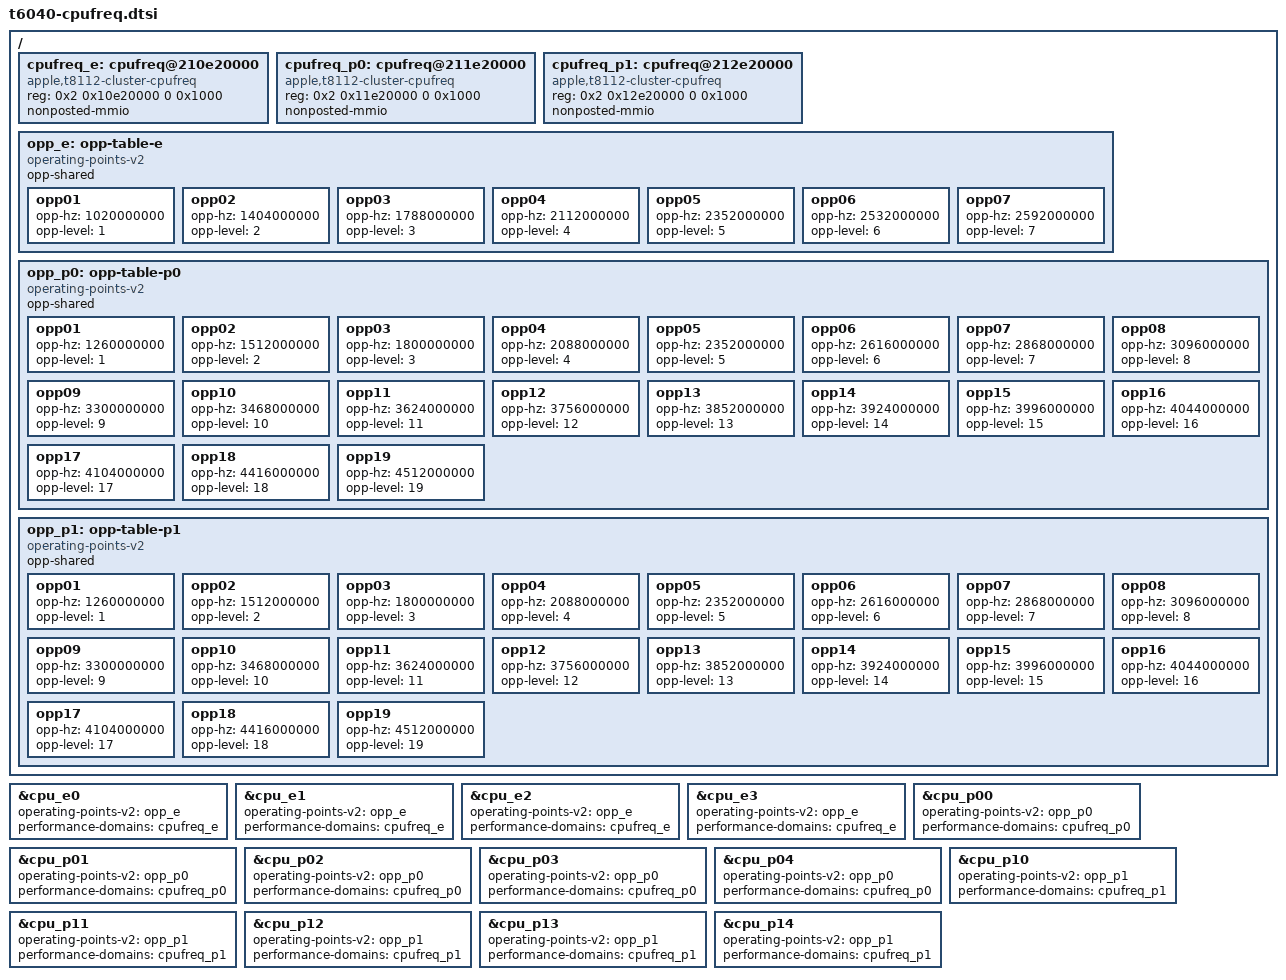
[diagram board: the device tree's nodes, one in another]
// SPDX-License-Identifier: GPL-2.0+ OR MIT
/*
 * T6040 cluster cpufreq: the three cluster DVFS blocks and their OPP tables, after CJ Damsleth's J614s
 * t6040-cpufreq.dtsi. Values from the J616s ADT: DVFS blocks /arm-io/pmgr reg[6] (E), reg[15] (P0) and reg[26]
 * (P1); frequencies voltage-states1/5/13-sram, word 0 = kHz; opp-level = the one-based p-state the driver writes.
 * Cluster n is MPIDR Aff1 = n; one table per cluster, as opp-shared means one clock domain per table.
 * nonposted-mmio on each block: the root has none, and SoC MMIO needs non-posted writes.
 */

/ {
	cpufreq_e: cpufreq@210e20000 {
		compatible = "apple,t8112-cluster-cpufreq";
		reg = <0x2 0x10e20000 0 0x1000>;
		nonposted-mmio;
		#performance-domain-cells = <0>;
	};

	cpufreq_p0: cpufreq@211e20000 {
		compatible = "apple,t8112-cluster-cpufreq";
		reg = <0x2 0x11e20000 0 0x1000>;
		nonposted-mmio;
		#performance-domain-cells = <0>;
	};

	cpufreq_p1: cpufreq@212e20000 {
		compatible = "apple,t8112-cluster-cpufreq";
		reg = <0x2 0x12e20000 0 0x1000>;
		nonposted-mmio;
		#performance-domain-cells = <0>;
	};

	opp_e: opp-table-e {
		compatible = "operating-points-v2";
		opp-shared;

		opp01 { opp-hz = /bits/ 64 <1020000000>; opp-level = <1>; };
		opp02 { opp-hz = /bits/ 64 <1404000000>; opp-level = <2>; };
		opp03 { opp-hz = /bits/ 64 <1788000000>; opp-level = <3>; };
		opp04 { opp-hz = /bits/ 64 <2112000000>; opp-level = <4>; };
		opp05 { opp-hz = /bits/ 64 <2352000000>; opp-level = <5>; };
		opp06 { opp-hz = /bits/ 64 <2532000000>; opp-level = <6>; };
		opp07 { opp-hz = /bits/ 64 <2592000000>; opp-level = <7>; };
	};

	opp_p0: opp-table-p0 {
		compatible = "operating-points-v2";
		opp-shared;

		opp01 { opp-hz = /bits/ 64 <1260000000>; opp-level = <1>; };
		opp02 { opp-hz = /bits/ 64 <1512000000>; opp-level = <2>; };
		opp03 { opp-hz = /bits/ 64 <1800000000>; opp-level = <3>; };
		opp04 { opp-hz = /bits/ 64 <2088000000>; opp-level = <4>; };
		opp05 { opp-hz = /bits/ 64 <2352000000>; opp-level = <5>; };
		opp06 { opp-hz = /bits/ 64 <2616000000>; opp-level = <6>; };
		opp07 { opp-hz = /bits/ 64 <2868000000>; opp-level = <7>; };
		opp08 { opp-hz = /bits/ 64 <3096000000>; opp-level = <8>; };
		opp09 { opp-hz = /bits/ 64 <3300000000>; opp-level = <9>; };
		opp10 { opp-hz = /bits/ 64 <3468000000>; opp-level = <10>; };
		opp11 { opp-hz = /bits/ 64 <3624000000>; opp-level = <11>; };
		opp12 { opp-hz = /bits/ 64 <3756000000>; opp-level = <12>; };
		opp13 { opp-hz = /bits/ 64 <3852000000>; opp-level = <13>; };
		opp14 { opp-hz = /bits/ 64 <3924000000>; opp-level = <14>; };
		opp15 { opp-hz = /bits/ 64 <3996000000>; opp-level = <15>; };
		opp16 { opp-hz = /bits/ 64 <4044000000>; opp-level = <16>; };
		opp17 { opp-hz = /bits/ 64 <4104000000>; opp-level = <17>; };
		opp18 { opp-hz = /bits/ 64 <4416000000>; opp-level = <18>; };
		opp19 { opp-hz = /bits/ 64 <4512000000>; opp-level = <19>; };
	};

	opp_p1: opp-table-p1 {
		compatible = "operating-points-v2";
		opp-shared;

		opp01 { opp-hz = /bits/ 64 <1260000000>; opp-level = <1>; };
		opp02 { opp-hz = /bits/ 64 <1512000000>; opp-level = <2>; };
		opp03 { opp-hz = /bits/ 64 <1800000000>; opp-level = <3>; };
		opp04 { opp-hz = /bits/ 64 <2088000000>; opp-level = <4>; };
		opp05 { opp-hz = /bits/ 64 <2352000000>; opp-level = <5>; };
		opp06 { opp-hz = /bits/ 64 <2616000000>; opp-level = <6>; };
		opp07 { opp-hz = /bits/ 64 <2868000000>; opp-level = <7>; };
		opp08 { opp-hz = /bits/ 64 <3096000000>; opp-level = <8>; };
		opp09 { opp-hz = /bits/ 64 <3300000000>; opp-level = <9>; };
		opp10 { opp-hz = /bits/ 64 <3468000000>; opp-level = <10>; };
		opp11 { opp-hz = /bits/ 64 <3624000000>; opp-level = <11>; };
		opp12 { opp-hz = /bits/ 64 <3756000000>; opp-level = <12>; };
		opp13 { opp-hz = /bits/ 64 <3852000000>; opp-level = <13>; };
		opp14 { opp-hz = /bits/ 64 <3924000000>; opp-level = <14>; };
		opp15 { opp-hz = /bits/ 64 <3996000000>; opp-level = <15>; };
		opp16 { opp-hz = /bits/ 64 <4044000000>; opp-level = <16>; };
		opp17 { opp-hz = /bits/ 64 <4104000000>; opp-level = <17>; };
		opp18 { opp-hz = /bits/ 64 <4416000000>; opp-level = <18>; };
		opp19 { opp-hz = /bits/ 64 <4512000000>; opp-level = <19>; };
	};
};

/* #cooling-cells on every CPU: the cpufreq cooling device of a cluster belongs to its policy CPU. */
&cpu_e0 { operating-points-v2 = <&opp_e>; performance-domains = <&cpufreq_e>; #cooling-cells = <2>; };
&cpu_e1 { operating-points-v2 = <&opp_e>; performance-domains = <&cpufreq_e>; #cooling-cells = <2>; };
&cpu_e2 { operating-points-v2 = <&opp_e>; performance-domains = <&cpufreq_e>; #cooling-cells = <2>; };
&cpu_e3 { operating-points-v2 = <&opp_e>; performance-domains = <&cpufreq_e>; #cooling-cells = <2>; };
&cpu_p00 { operating-points-v2 = <&opp_p0>; performance-domains = <&cpufreq_p0>; #cooling-cells = <2>; };
&cpu_p01 { operating-points-v2 = <&opp_p0>; performance-domains = <&cpufreq_p0>; #cooling-cells = <2>; };
&cpu_p02 { operating-points-v2 = <&opp_p0>; performance-domains = <&cpufreq_p0>; #cooling-cells = <2>; };
&cpu_p03 { operating-points-v2 = <&opp_p0>; performance-domains = <&cpufreq_p0>; #cooling-cells = <2>; };
&cpu_p04 { operating-points-v2 = <&opp_p0>; performance-domains = <&cpufreq_p0>; #cooling-cells = <2>; };
&cpu_p10 { operating-points-v2 = <&opp_p1>; performance-domains = <&cpufreq_p1>; #cooling-cells = <2>; };
&cpu_p11 { operating-points-v2 = <&opp_p1>; performance-domains = <&cpufreq_p1>; #cooling-cells = <2>; };
&cpu_p12 { operating-points-v2 = <&opp_p1>; performance-domains = <&cpufreq_p1>; #cooling-cells = <2>; };
&cpu_p13 { operating-points-v2 = <&opp_p1>; performance-domains = <&cpufreq_p1>; #cooling-cells = <2>; };
&cpu_p14 { operating-points-v2 = <&opp_p1>; performance-domains = <&cpufreq_p1>; #cooling-cells = <2>; };
